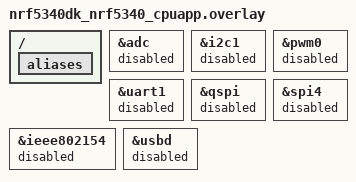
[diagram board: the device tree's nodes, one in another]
/*
 * Copyright (c) 2025 Nordic Semiconductor ASA
 *
 * SPDX-License-Identifier: LicenseRef-Nordic-5-Clause
 */

/ {
	aliases {
		/delete-property/ sw2;
		/delete-property/ sw3;
	};
};

/delete-node/ &button2;
/delete-node/ &button3;

/* Disable unused peripherals to reduce power consumption */
&adc {
	status = "disabled";
};

&i2c1 {
	status = "disabled";
};

&pwm0 {
	status = "disabled";
};

&uart1 {
	status = "disabled";
};

&qspi {
	status = "disabled";
};

&spi4 {
	status = "disabled";
};

&ieee802154 {
	status = "disabled";
};

&usbd {
	status = "disabled";
};
